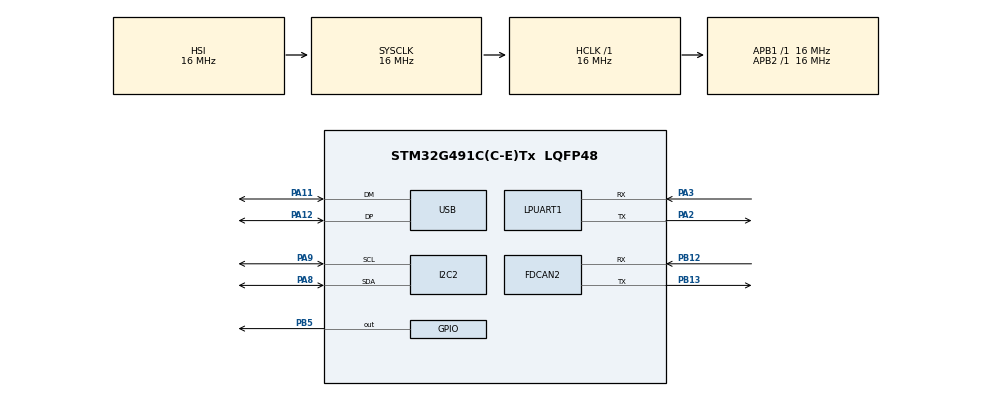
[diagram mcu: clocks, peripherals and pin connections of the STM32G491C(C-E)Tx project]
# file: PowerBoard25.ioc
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FDCAN2.CalculateBaudRateNominal=333333
FDCAN2.CalculateTimeBitNominal=3000
FDCAN2.CalculateTimeQuantumNominal=1000.0
FREERTOS.Tasks01=defaultTask,24,128,StartDefaultTask,Default,NULL,Dynamic,NULL,NULL
FREERTOS.configENABLE_FPU=1
FREERTOS.configUSE_NEWLIB_REENTRANT=1
I2C2.Timing=0x00503D58
Mcu.Family=STM32G4
Mcu.Name=STM32G491C(C-E)Tx
Mcu.Package=LQFP48
NVIC.PriorityGroup=NVIC_PRIORITYGROUP_4
NVIC.USB_LP_IRQn=true\:5\:0\:false\:false\:true\:true\:false\:true\:true
PA11.Mode=Device
PA11.Signal=USB_DM
PA12.Mode=Device
PA12.Signal=USB_DP
PA13.Mode=JTAG_5_pins
PA13.Signal=SYS_JTMS-SWDIO
PA14.Mode=JTAG_5_pins
PA14.Signal=SYS_JTCK-SWCLK
PA15.Mode=JTAG_5_pins
PA15.Signal=SYS_JTDI
PA2.Mode=Asynchronous
PA2.Signal=LPUART1_TX
PA3.Mode=Asynchronous
PA3.Signal=LPUART1_RX
PA8.Mode=I2C
PA8.Signal=I2C2_SDA
PA9.Mode=I2C
PA9.Signal=I2C2_SCL
PB12.Mode=FDCAN_Activate
PB12.Signal=FDCAN2_RX
PB13.Mode=FDCAN_Activate
PB13.Signal=FDCAN2_TX
PB3.Mode=JTAG_5_pins
PB3.Signal=SYS_JTDO-SWO
PB4.Mode=JTAG_5_pins
PB4.Signal=SYS_JTRST
PB5.Signal=GPIO_Output
PC14-OSC32_IN.Mode=LSE-External-Oscillator
PC14-OSC32_IN.Signal=RCC_OSC32_IN
PC15-OSC32_OUT.Mode=LSE-External-Oscillator
PC15-OSC32_OUT.Signal=RCC_OSC32_OUT
PF0-OSC_IN.Mode=HSE-External-Oscillator
PF0-OSC_IN.Signal=RCC_OSC_IN
PF1-OSC_OUT.Mode=HSE-External-Oscillator
PF1-OSC_OUT.Signal=RCC_OSC_OUT
ProjectManager.HeapSize=0x200
ProjectManager.StackSize=0x400
ProjectManager.TargetToolchain=STM32CubeIDE
RCC.AHBFreq_Value=16000000
RCC.APB1Freq_Value=16000000
RCC.APB1TimFreq_Value=16000000
RCC.APB2Freq_Value=16000000
RCC.APB2TimFreq_Value=16000000
RCC.CortexFreq_Value=16000000
RCC.EXTERNAL_CLOCK_VALUE=12288000
RCC.HCLKFreq_Value=16000000
RCC.HSE_VALUE=8000000
RCC.HSI48_VALUE=48000000
RCC.HSI_VALUE=16000000
RCC.SYSCLKFreq_VALUE=16000000
RCC.VCOOutputFreq_Value=128000000
USB_DEVICE.CLASS_NAME_FS=CDC
USB_DEVICE.VirtualMode=Cdc
USB_DEVICE.VirtualModeFS=Cdc_FS
VP_FREERTOS_VS_CMSIS_V2.Mode=CMSIS_V2
VP_SYS_VS_DBSignals.Mode=DisableDeadBatterySignals
VP_USB_DEVICE_VS_USB_DEVICE_CDC_FS.Mode=CDC_FS
board=custom

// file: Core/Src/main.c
/* USER CODE BEGIN Header */
/**
  ******************************************************************************
  * @file           : main.c
  * @brief          : Main program body
  ******************************************************************************
  * @attention
  *
  * Copyright (c) 2025 STMicroelectronics.
  * All rights reserved.
  *
  * This software is licensed under terms that can be found in the LICENSE file
  * in the root directory of this software component.
  * If no LICENSE file comes with this software, it is provided AS-IS.
  *
  ******************************************************************************
  */
/* USER CODE END Header */
#include "main.h"
#include "cmsis_os.h"

/* USER CODE BEGIN Includes */
#include "Drivers/LTC2990.h"
#include <stdarg.h>
/* USER CODE END Includes */

/* USER CODE BEGIN PD */
#define PRINT_BUFFER_SIZE     256
/* USER CODE END PD */

FDCAN_HandleTypeDef hfdcan2;

I2C_HandleTypeDef hi2c2;

UART_HandleTypeDef hlpuart1;

PCD_HandleTypeDef hpcd_USB_FS;

/* Definitions for defaultTask */
osThreadId_t defaultTaskHandle;
const osThreadAttr_t defaultTask_attributes = {
  .name = "defaultTask",
  .priority = (osPriority_t) osPriorityNormal,
  .stack_size = 128 * 4
};

void SystemClock_Config(void);
static void MX_GPIO_Init(void);
static void MX_FDCAN2_Init(void);
static void MX_USB_PCD_Init(void);
static void MX_I2C2_Init(void);
static void MX_LPUART1_UART_Init(void);
void StartDefaultTask(void *argument);

/* USER CODE BEGIN 0 */
extern void CDC_Transmit_Print(const char *format, ...) {
	char buf[PRINT_BUFFER_SIZE];
	va_list args;
	va_start(args, format);
	int n = vsprintf(buf, format, args);
	CDC_Transmit_FS(buf, n);
}
/* USER CODE END 0 */

int main(void)
{

  /* MCU Configuration--------------------------------------------------------*/

  /* Reset of all peripherals, Initializes the Flash interface and the Systick. */
  HAL_Init();

  /* Configure the system clock */
  SystemClock_Config();

  /* Initialize all configured peripherals */
  MX_GPIO_Init();
  MX_FDCAN2_Init();
  MX_USB_PCD_Init();
  MX_I2C2_Init();
  MX_LPUART1_UART_Init();

  /* Init scheduler */
  osKernelInitialize();

  /* Create the thread(s) */
  /* creation of defaultTask */
  defaultTaskHandle = osThreadNew(StartDefaultTask, NULL, &defaultTask_attributes);

  /* Start scheduler */
  osKernelStart();

  /* We should never get here as control is now taken by the scheduler */

  /* Infinite loop */
  while (1)
  {

  }
}

void SystemClock_Config(void)
{
  RCC_OscInitTypeDef RCC_OscInitStruct = {0};
  RCC_ClkInitTypeDef RCC_ClkInitStruct = {0};

  /** Configure the main internal regulator output voltage
  */
  HAL_PWREx_ControlVoltageScaling(PWR_REGULATOR_VOLTAGE_SCALE1);

  /** Initializes the RCC Oscillators according to the specified parameters
  * in the RCC_OscInitTypeDef structure.
  */
  RCC_OscInitStruct.OscillatorType = RCC_OSCILLATORTYPE_HSI|RCC_OSCILLATORTYPE_HSI48;
  RCC_OscInitStruct.HSIState = RCC_HSI_ON;
  RCC_OscInitStruct.HSICalibrationValue = RCC_HSICALIBRATION_DEFAULT;
  RCC_OscInitStruct.HSI48State = RCC_HSI48_ON;
  RCC_OscInitStruct.PLL.PLLState = RCC_PLL_NONE;
  if (HAL_RCC_OscConfig(&RCC_OscInitStruct) != HAL_OK)
  {
    Error_Handler();
  }

  /** Initializes the CPU, AHB and APB buses clocks
  */
  RCC_ClkInitStruct.ClockType = RCC_CLOCKTYPE_HCLK|RCC_CLOCKTYPE_SYSCLK
                              |RCC_CLOCKTYPE_PCLK1|RCC_CLOCKTYPE_PCLK2;
  RCC_ClkInitStruct.SYSCLKSource = RCC_SYSCLKSOURCE_HSI;
  RCC_ClkInitStruct.AHBCLKDivider = RCC_SYSCLK_DIV1;
  RCC_ClkInitStruct.APB1CLKDivider = RCC_HCLK_DIV1;
  RCC_ClkInitStruct.APB2CLKDivider = RCC_HCLK_DIV1;

  if (HAL_RCC_ClockConfig(&RCC_ClkInitStruct, FLASH_LATENCY_0) != HAL_OK)
  {
    Error_Handler();
  }
}

static void MX_FDCAN2_Init(void)
{

  hfdcan2.Instance = FDCAN2;
  hfdcan2.Init.ClockDivider = FDCAN_CLOCK_DIV1;
  hfdcan2.Init.FrameFormat = FDCAN_FRAME_CLASSIC;
  hfdcan2.Init.Mode = FDCAN_MODE_NORMAL;
  hfdcan2.Init.AutoRetransmission = DISABLE;
  hfdcan2.Init.TransmitPause = DISABLE;
  hfdcan2.Init.ProtocolException = DISABLE;
  hfdcan2.Init.NominalPrescaler = 16;
  hfdcan2.Init.NominalSyncJumpWidth = 1;
  hfdcan2.Init.NominalTimeSeg1 = 1;
  hfdcan2.Init.NominalTimeSeg2 = 1;
  hfdcan2.Init.DataPrescaler = 1;
  hfdcan2.Init.DataSyncJumpWidth = 1;
  hfdcan2.Init.DataTimeSeg1 = 1;
  hfdcan2.Init.DataTimeSeg2 = 1;
  hfdcan2.Init.StdFiltersNbr = 0;
  hfdcan2.Init.ExtFiltersNbr = 0;
  hfdcan2.Init.TxFifoQueueMode = FDCAN_TX_FIFO_OPERATION;
  if (HAL_FDCAN_Init(&hfdcan2) != HAL_OK)
  {
    Error_Handler();
  }

}

static void MX_I2C2_Init(void)
{

  hi2c2.Instance = I2C2;
  hi2c2.Init.Timing = 0x00503D58;
  hi2c2.Init.OwnAddress1 = 0;
  hi2c2.Init.AddressingMode = I2C_ADDRESSINGMODE_7BIT;
  hi2c2.Init.DualAddressMode = I2C_DUALADDRESS_DISABLE;
  hi2c2.Init.OwnAddress2 = 0;
  hi2c2.Init.OwnAddress2Masks = I2C_OA2_NOMASK;
  hi2c2.Init.GeneralCallMode = I2C_GENERALCALL_DISABLE;
  hi2c2.Init.NoStretchMode = I2C_NOSTRETCH_DISABLE;
  if (HAL_I2C_Init(&hi2c2) != HAL_OK)
  {
    Error_Handler();
  }

  /** Configure Analogue filter
  */
  if (HAL_I2CEx_ConfigAnalogFilter(&hi2c2, I2C_ANALOGFILTER_ENABLE) != HAL_OK)
  {
    Error_Handler();
  }

  /** Configure Digital filter
  */
  if (HAL_I2CEx_ConfigDigitalFilter(&hi2c2, 0) != HAL_OK)
  {
    Error_Handler();
  }

}

static void MX_LPUART1_UART_Init(void)
{

  hlpuart1.Instance = LPUART1;
  hlpuart1.Init.BaudRate = 209700;
  hlpuart1.Init.WordLength = UART_WORDLENGTH_8B;
  hlpuart1.Init.StopBits = UART_STOPBITS_1;
  hlpuart1.Init.Parity = UART_PARITY_NONE;
  hlpuart1.Init.Mode = UART_MODE_TX_RX;
  hlpuart1.Init.HwFlowCtl = UART_HWCONTROL_NONE;
  hlpuart1.Init.OneBitSampling = UART_ONE_BIT_SAMPLE_DISABLE;
  hlpuart1.Init.ClockPrescaler = UART_PRESCALER_DIV1;
  hlpuart1.AdvancedInit.AdvFeatureInit = UART_ADVFEATURE_NO_INIT;
  if (HAL_UART_Init(&hlpuart1) != HAL_OK)
  {
    Error_Handler();
  }
  if (HAL_UARTEx_SetTxFifoThreshold(&hlpuart1, UART_TXFIFO_THRESHOLD_1_8) != HAL_OK)
  {
    Error_Handler();
  }
  if (HAL_UARTEx_SetRxFifoThreshold(&hlpuart1, UART_RXFIFO_THRESHOLD_1_8) != HAL_OK)
  {
    Error_Handler();
  }
  if (HAL_UARTEx_DisableFifoMode(&hlpuart1) != HAL_OK)
  {
    Error_Handler();
  }

}

static void MX_USB_PCD_Init(void)
{

  hpcd_USB_FS.Instance = USB;
  hpcd_USB_FS.Init.dev_endpoints = 8;
  hpcd_USB_FS.Init.speed = PCD_SPEED_FULL;
  hpcd_USB_FS.Init.phy_itface = PCD_PHY_EMBEDDED;
  hpcd_USB_FS.Init.Sof_enable = DISABLE;
  hpcd_USB_FS.Init.low_power_enable = DISABLE;
  hpcd_USB_FS.Init.lpm_enable = DISABLE;
  hpcd_USB_FS.Init.battery_charging_enable = DISABLE;
  if (HAL_PCD_Init(&hpcd_USB_FS) != HAL_OK)
  {
    Error_Handler();
  }

}

static void MX_GPIO_Init(void)
{
  GPIO_InitTypeDef GPIO_InitStruct = {0};

  /* GPIO Ports Clock Enable */
  __HAL_RCC_GPIOC_CLK_ENABLE();
  __HAL_RCC_GPIOF_CLK_ENABLE();
  __HAL_RCC_GPIOA_CLK_ENABLE();
  __HAL_RCC_GPIOB_CLK_ENABLE();

  /*Configure GPIO pin Output Level */
  HAL_GPIO_WritePin(GPIOB, GPIO_PIN_5, GPIO_PIN_RESET);

  /*Configure GPIO pin : PB5 */
  GPIO_InitStruct.Pin = GPIO_PIN_5;
  GPIO_InitStruct.Mode = GPIO_MODE_OUTPUT_PP;
  GPIO_InitStruct.Pull = GPIO_NOPULL;
  GPIO_InitStruct.Speed = GPIO_SPEED_FREQ_LOW;
  HAL_GPIO_Init(GPIOB, &GPIO_InitStruct);

}

void StartDefaultTask(void *argument)
{
  for(;;)
  {
    osDelay(1);
  }
}

void Error_Handler(void)
{
  __disable_irq();
  while (1)
  {
  }
}
